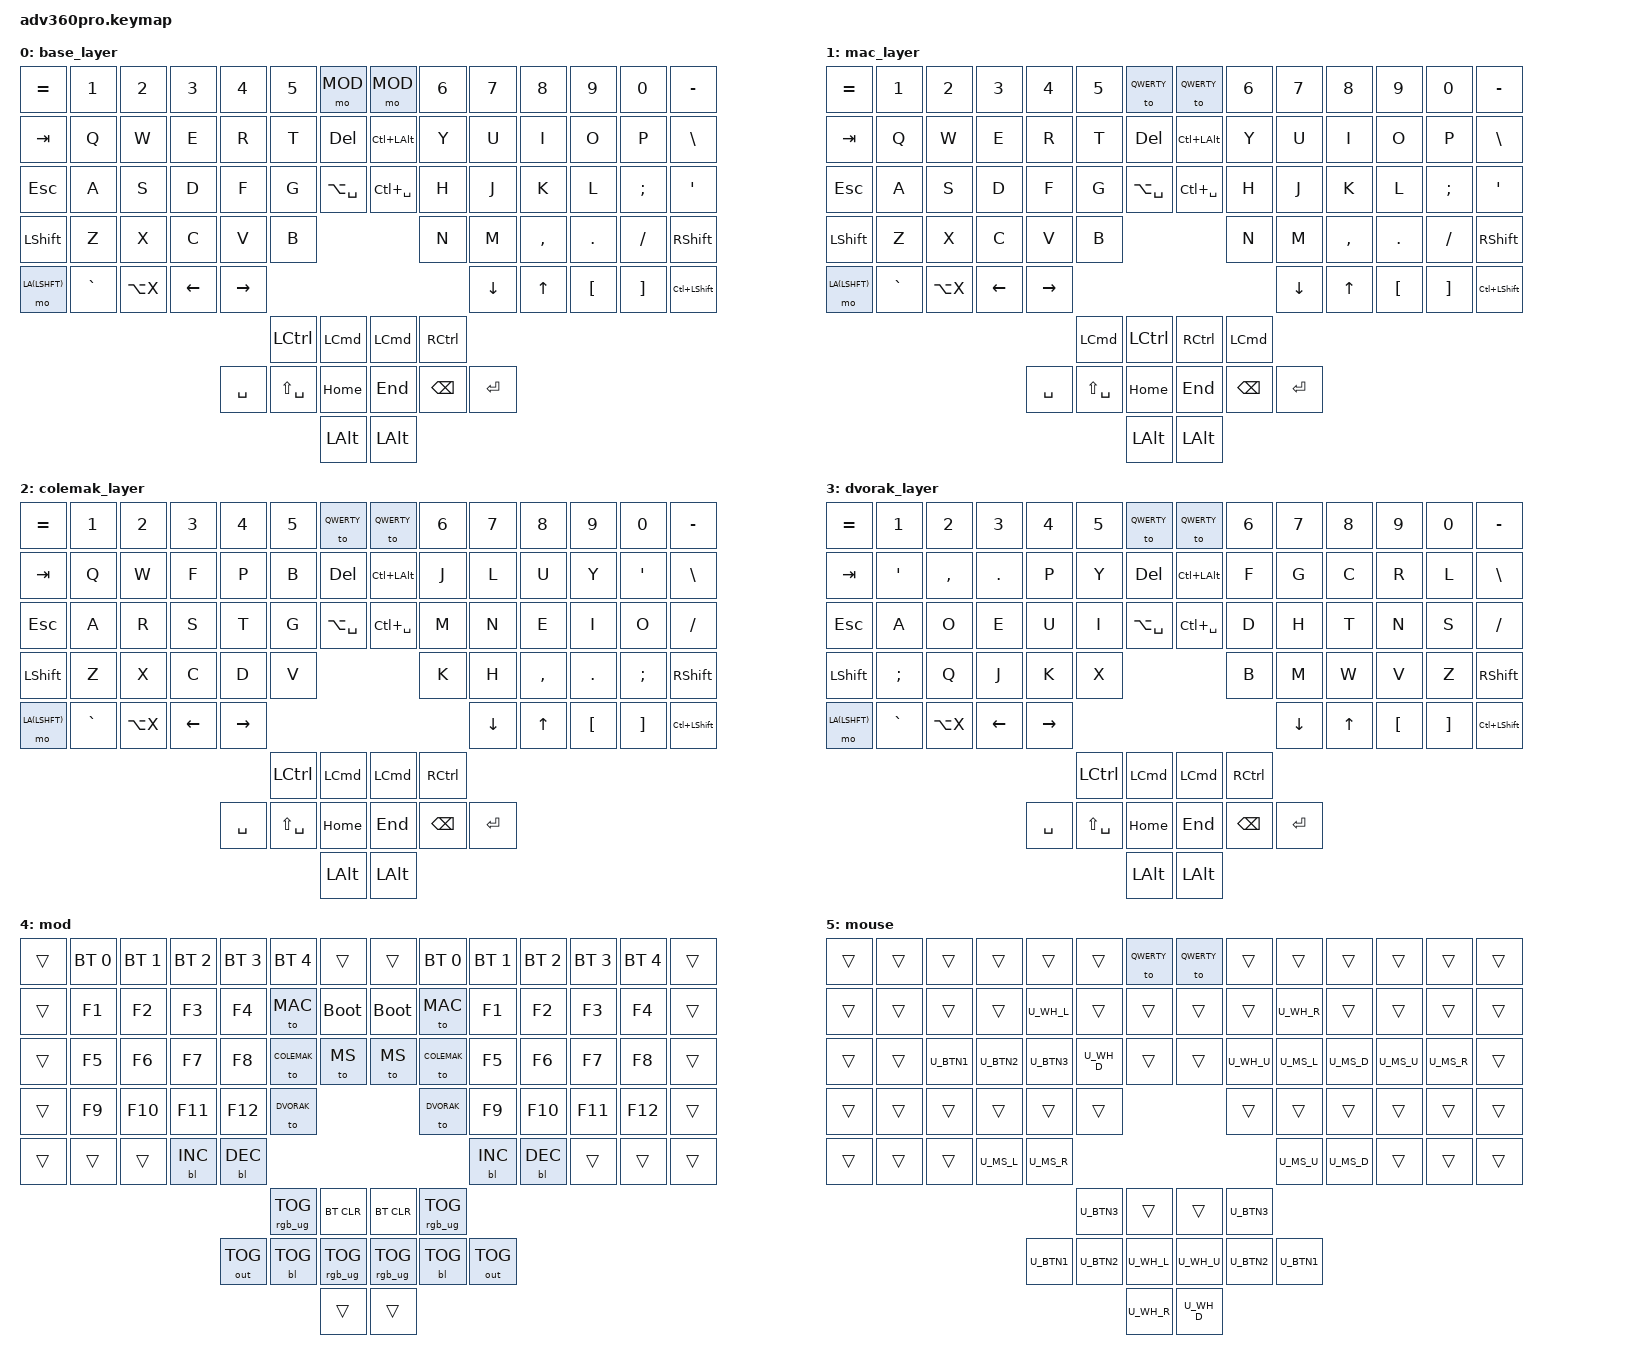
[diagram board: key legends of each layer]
#include <behaviors.dtsi>
#include <dt-bindings/zmk/keys.h>
#include <dt-bindings/zmk/bt.h>
#include <dt-bindings/zmk/outputs.h>
#include <dt-bindings/zmk/rgb.h>
#include <dt-bindings/zmk/backlight.h>

/* definitions for mouse layer */
#include "mouse.dtsi"

#define ___ &trans

#define QWERTY 0
#define MAC 1
#define COLEMAK 2
#define DVORAK 3
#define MOD 4
#define MS 5

/ {
    /* remove unused keys from layout and move thumb cluster to bottom */
    chosen {
        zmk,matrix_transform = &urobs_transform;
    };

    keymap {
        compatible = "zmk,keymap";

        base_layer {
            bindings = <
                &kp EQUAL      &kp N1    &kp N2    &kp N3    &kp N4    &kp N5    &mo MOD        &mo MOD       &kp N6    &kp N7    &kp N8    &kp N9    &kp N0    &kp MINUS
                &kp TAB        &kp Q     &kp W     &kp E     &kp R     &kp T     &kp DEL        &kp LC(LALT)  &kp Y     &kp U     &kp I     &kp O     &kp P     &kp BSLH
                &kp ESC        &kp A     &kp S     &kp D     &kp F     &kp G     &kp LA(SPACE)  &kp LC(SPACE) &kp H     &kp J     &kp K     &kp L     &kp SEMI  &kp SQT
                &kp LSHFT      &kp Z     &kp X     &kp C     &kp V     &kp B                                  &kp N     &kp M     &kp COMMA &kp DOT   &kp FSLH  &kp RSHFT
                &mo LA(LSHFT)  &kp GRAVE &kp LA(X) &kp LEFT  &kp RIGHT                                                  &kp DOWN  &kp UP    &kp LBKT  &kp RBKT  &kp LC(LSHFT)
                                                                       &kp LCTRL &kp LCMD       &kp LCMD  &kp RCTRL
                                                         &kp SPACE &kp LS(SPACE) &kp HOME       &kp END   &kp BSPC &kp ENTER
                                                                                 &kp LALT       &kp LALT
            >;
        };

        mac_layer {
            bindings = <
                &kp EQUAL      &kp N1    &kp N2    &kp N3    &kp N4    &kp N5    &to QWERTY     &to QWERTY    &kp N6    &kp N7    &kp N8    &kp N9    &kp N0    &kp MINUS
                &kp TAB        &kp Q     &kp W     &kp E     &kp R     &kp T     &kp DEL        &kp LC(LALT)  &kp Y     &kp U     &kp I     &kp O     &kp P     &kp BSLH
                &kp ESC        &kp A     &kp S     &kp D     &kp F     &kp G     &kp LA(SPACE)  &kp LC(SPACE) &kp H     &kp J     &kp K     &kp L     &kp SEMI  &kp SQT
                &kp LSHFT      &kp Z     &kp X     &kp C     &kp V     &kp B                                  &kp N     &kp M     &kp COMMA &kp DOT   &kp FSLH  &kp RSHFT
                &mo LA(LSHFT)  &kp GRAVE &kp LA(X) &kp LEFT  &kp RIGHT                                                  &kp DOWN  &kp UP    &kp LBKT  &kp RBKT  &kp LC(LSHFT)
                                                                       &kp LCMD  &kp LCTRL      &kp RCTRL &kp LCMD
                                                         &kp SPACE &kp LS(SPACE) &kp HOME       &kp END   &kp BSPC &kp ENTER
                                                                                 &kp LALT       &kp LALT
            >;
        };

        colemak_layer {
            bindings = <
                &kp EQUAL      &kp N1    &kp N2    &kp N3    &kp N4    &kp N5    &to QWERTY     &to QWERTY    &kp N6    &kp N7    &kp N8    &kp N9    &kp N0    &kp MINUS
                &kp TAB        &kp Q     &kp W     &kp F     &kp P     &kp B     &kp DEL        &kp LC(LALT)  &kp J     &kp L     &kp U     &kp Y     &kp SQT   &kp BSLH
                &kp ESC        &kp A     &kp R     &kp S     &kp T     &kp G     &kp LA(SPACE)  &kp LC(SPACE) &kp M     &kp N     &kp E     &kp I     &kp O     &kp FSLH
                &kp LSHFT      &kp Z     &kp X     &kp C     &kp D     &kp V                                  &kp K     &kp H     &kp COMMA &kp DOT   &kp SEMI  &kp RSHFT
                &mo LA(LSHFT)  &kp GRAVE &kp LA(X) &kp LEFT  &kp RIGHT                                                  &kp DOWN  &kp UP    &kp LBKT  &kp RBKT  &kp LC(LSHFT)
                                                                       &kp LCTRL &kp LCMD       &kp LCMD  &kp RCTRL
                                                         &kp SPACE &kp LS(SPACE) &kp HOME       &kp END   &kp BSPC &kp ENTER
                                                                                 &kp LALT       &kp LALT
            >;
        };

        dvorak_layer {
            bindings = <
                &kp EQUAL      &kp N1    &kp N2    &kp N3    &kp N4    &kp N5    &to QWERTY     &to QWERTY    &kp N6    &kp N7    &kp N8    &kp N9    &kp N0    &kp MINUS
                &kp TAB        &kp SQT   &kp COMMA &kp DOT   &kp P     &kp Y     &kp DEL        &kp LC(LALT)  &kp F     &kp G     &kp C     &kp R     &kp L     &kp BSLH
                &kp ESC        &kp A     &kp O     &kp E     &kp U     &kp I     &kp LA(SPACE)  &kp LC(SPACE) &kp D     &kp H     &kp T     &kp N     &kp S     &kp FSLH
                &kp LSHFT      &kp SEMI  &kp Q     &kp J     &kp K     &kp X                                  &kp B     &kp M     &kp W     &kp V     &kp Z     &kp RSHFT
                &mo LA(LSHFT)  &kp GRAVE &kp LA(X) &kp LEFT  &kp RIGHT                                                  &kp DOWN  &kp UP    &kp LBKT  &kp RBKT  &kp LC(LSHFT)
                                                                       &kp LCTRL &kp LCMD       &kp LCMD  &kp RCTRL
                                                         &kp SPACE &kp LS(SPACE) &kp HOME       &kp END   &kp BSPC &kp ENTER
                                                                                 &kp LALT       &kp LALT
            >;
        };

        mod {
            bindings = <
                ___       &bt BT_SEL 0 &bt BT_SEL 1 &bt BT_SEL 2 &bt BT_SEL 3 &bt BT_SEL 4 ___              ___         &bt BT_SEL 0 &bt BT_SEL 1 &bt BT_SEL 2 &bt BT_SEL 3 &bt BT_SEL 4 ___
                ___       &kp F1       &kp F2       &kp F3       &kp F4       &to MAC      &bootloader      &bootloader &to MAC      &kp F1       &kp F2       &kp F3       &kp F4       ___
                ___       &kp F5       &kp F6       &kp F7       &kp F8       &to COLEMAK  &to MS           &to MS      &to COLEMAK  &kp F5       &kp F6       &kp F7       &kp F8       ___
                ___       &kp F9       &kp F10      &kp F11      &kp F12      &to DVORAK                                &to DVORAK   &kp F9       &kp F10      &kp F11      &kp F12      ___
                ___       ___          ___          &bl BL_INC   &bl BL_DEC                                                          &bl BL_INC   &bl BL_DEC   ___          ___          ___
                                                                          &rgb_ug RGB_TOG  &bt BT_CLR       &bt BT_CLR      &rgb_ug RGB_TOG
                                                  &out OUT_TOG             &bl BL_TOG &rgb_ug RGB_TOG       &rgb_ug RGB_TOG &bl BL_TOG      &out OUT_TOG
                                                                                                  ___       ___
            >;
        };

        mouse {
            bindings = <
                ___       ___       ___       ___       ___       ___       &to QWERTY     &to QWERTY ___       ___       ___       ___       ___       ___
                ___       ___       ___       ___       U_WH_L    ___       ___            ___        ___       U_WH_R    ___       ___       ___       ___
                ___       ___       U_BTN1    U_BTN2    U_BTN3    U_WH_D    ___            ___        U_WH_U    U_MS_L    U_MS_D    U_MS_U    U_MS_R    ___
                ___       ___       ___       ___       ___       ___                                 ___       ___       ___       ___       ___       ___
                ___       ___       ___       U_MS_L    U_MS_R                                                  U_MS_U    U_MS_D    ___       ___       ___
                                                                  U_BTN3    ___            ___        U_BTN3
                                                        U_BTN1    U_BTN2    U_WH_L         U_WH_U     U_BTN2    U_BTN1
                                                                            U_WH_R         U_WH_D
            >;
        };

    };

};

